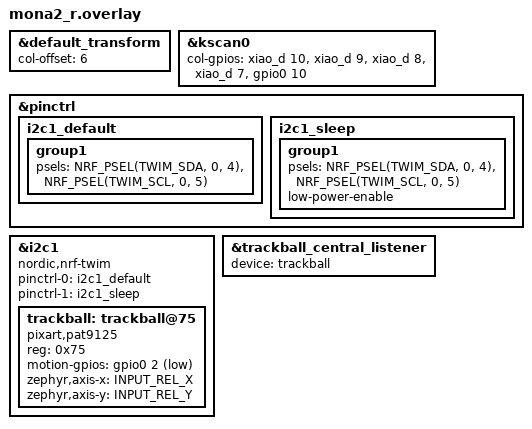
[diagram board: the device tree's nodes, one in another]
#include "mona2.dtsi"
#include <input/processors.dtsi>
#include <zephyr/dt-bindings/input/input-event-codes.h>
#include <input/processors/report_rate_limit.dtsi>


&default_transform {
    col-offset = <6>;
};

&kscan0 {
        col-gpios
            = <&xiao_d 10 GPIO_ACTIVE_HIGH>
            , <&xiao_d 9 GPIO_ACTIVE_HIGH> 
            , <&xiao_d 8 GPIO_ACTIVE_HIGH> 
            , <&xiao_d 7 GPIO_ACTIVE_HIGH> 
            , <&gpio0 10 GPIO_ACTIVE_HIGH>
            ;
};

&pinctrl {
    i2c1_default: i2c1_default {
        group1 {
            psels = <NRF_PSEL(TWIM_SDA, 0, 4)>,
                    <NRF_PSEL(TWIM_SCL, 0, 5)>;
        };
    };

    i2c1_sleep: i2c1_sleep {
        group1 {
            psels = <NRF_PSEL(TWIM_SDA, 0, 4)>,
                    <NRF_PSEL(TWIM_SCL, 0, 5)>;
            low-power-enable;
        };
    };
};

&i2c1 {
    status = "okay";
    compatible = "nordic,nrf-twim";
    pinctrl-0 = <&i2c1_default>;
    pinctrl-1 = <&i2c1_sleep>;
    pinctrl-names = "default", "sleep";

    trackball: trackball@75 {
        compatible = "pixart,pat9125";
        reg = <0x75>;
        status = "okay";
        motion-gpios = <&gpio0 2 (GPIO_ACTIVE_LOW | GPIO_PULL_UP)>;
        zephyr,axis-x = <INPUT_REL_X>;
        zephyr,axis-y = <INPUT_REL_Y>;
    };
};

&trackball_central_listener {
    status = "okay";
    device = <&trackball>;
};


